# RN8XXX_V2 register map
File version: 1.0
Registers are 32-bit, read-write, reset 0x0 unless marked. A register's access mark holds for its fields unless they carry their own. Offsets are from the block's base; [hi:lo] are bit positions; {n}, {i} and the like mark numbered series.

## INTC — interrupt controller for off-chip interrupt requests
Base 0x40044000
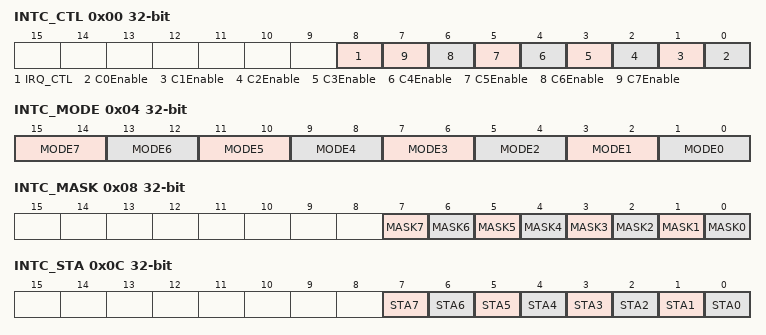
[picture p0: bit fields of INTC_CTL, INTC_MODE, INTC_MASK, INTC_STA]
0x00 INTC_CTL — INTC control register
  [8] IRQ_CTL — external interrupt mode selection
    0=disabled (INT0~INT7 not use IRQ_CTL to indicate interrupt, refer to STA.EXIT[7:0]); 1=enabled (INT0~INT7 share EXIT0 IRQ vector, check STA for which interrupt accour)
  [n] C{n}Enable (n=0..7) — external interrupt request channel {n} enable
    0=disabled (interrupt request disabled); 1=enabled (interrupt request enabled)
0x04 INTC_MODE
  [all] fields
    0=rising_edge (every rising edge found on input recognized as a valid interrupt request); 1=falling_edge (every falling edge found on input recognized as a valid interrupt request); 2=both_edge (both rising and falling edge found on input recognized as a valid interrupt request)
  [15:14] MODE7 — external interrupt request channel No.7 mode selection
  [13:12] MODE6 — external interrupt request channel No.6 mode selection
  [11:10] MODE5 — external interrupt request channel No.5 mode selection
  [9:8] MODE4 — external interrupt request channel No.4 mode selection
  [7:6] MODE3 — external interrupt request channel No.3 mode selection
  [5:4] MODE2 — external interrupt request channel No.2 mode selection
  [3:2] MODE1 — external interrupt request channel No.1 mode selection
  [1:0] MODE0 — external interrupt request channel No.0 mode selection
0x08 INTC_MASK
  [all] fields
    0=disabled; 1=enabled
  [7] MASK7 — external interrupt request channel No.7 mask selection
  [6] MASK6 — external interrupt request channel No.6 mask selection
  [5] MASK5 — external interrupt request channel No.5 mask selection
  [4] MASK4 — external interrupt request channel No.4 mask selection
  [3] MASK3 — external interrupt request channel No.3 mask selection
  [2] MASK2 — external interrupt request channel No.2 mask selection
  [1] MASK1 — external interrupt request channel No.1 mask selection
  [0] MASK0 — external interrupt request channel No.0 mask selection
0x0C INTC_STA — Extern interrupt status register
  [all] fields
    0=not_pending (no interrupt request event found); 1=pending ((one or more)interrupt request event found)
  [7] STA7 write-1-clears — external interrupt request channel No.7 raw status
  [6] STA6 write-1-clears — external interrupt request channel No.6 raw status
  [5] STA5 write-1-clears — external interrupt request channel No.5 raw status
  [4] STA4 write-1-clears — external interrupt request channel No.4 raw status
  [3] STA3 write-1-clears — external interrupt request channel No.3 raw status
  [2] STA2 write-1-clears — external interrupt request channel No.2 raw status
  [1] STA1 write-1-clears — external interrupt request channel No.1 raw status
  [0] STA0 write-1-clears — external interrupt request channel No.0 raw status

## I2C — I2C controller
Base 0x40024000
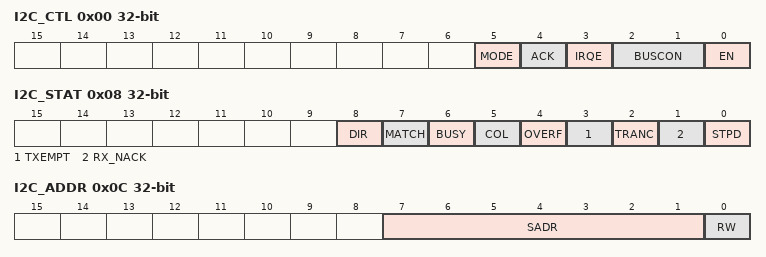
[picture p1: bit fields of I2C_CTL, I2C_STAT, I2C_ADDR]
0x00 I2C_CTL — control
  [5] MODE — mode selection
    0=slave (I2C slave mode); 1=master (I2C master mode)
  [4] ACK — ACK generation enable
    0=disable (do not generate ACK signal when ninth SCL (clock) received); 1=enable (generate ACK signal when ninth SCL (clock) received)
  [3] IRQE — interrupt enable
    0=disable (do not generate interrupt request); 1=enable (generate interrupt request when needed)
  [2:1] BUSCON — bus control signal generation
    0=no_action (do not generate any bus control signal); 1=start (generate I2C start signal); 2=stop (generate I2C stop signal); 3=reserved (do not use)
  [0] EN — module enable
    0=disable (transmit and receive engine disabled); 1=enable (transmit and receive engine enabled)
0x04 I2C_CLK reset 0x1 — clock config
  [2:0] CLKDIV — bus clock divisor
    0=hs0_d6 (high speed mode0 (divisor is 6).applicable when frequency of system clock is 1.8432MHz); 1=hs0_d10 (high speed mode1 (divisor is 10).applicable when frequency of system clock is 3.6864MHz); 2=hs0_d20/ls0_d20 (high speed mode2 (divisor is 20).applicable when frequency of system clock is 7.3728MHz. Or low speed mode0 (divisor is 20).applicable when frequency of system clock is 1.8432MHz.); 3=hs0_d38/ls0_d38 (high speed mode3 (divisor is 38).applicable when frequency of system clock is 14.7456MHz. Or low speed mode1 (divisor is 38).applicable when frequency of system clock is 3.6864MHz); 4=hs0_d76/ls0_d76 (high speed mode4 (divisor is 76).applicable when frequency of system clock is 29.4912MHz. Or low speed mode2 (divisor is 76).applicable when frequency of system clock is 7.3728MHz); 5=ls0_d152 (low speed mode3 (divisor is 152).applicable when frequency of system clock is 14.7456MHz); 6=ls0_d76 (low speed mode4 (divisor is 304).applicable when frequency of system clock is 29.4912MHz); 7=reserved2 (do not use)
0x08 I2C_STAT — status
  [8] DIR ro — bus transfer direction
    0=transmiting; 1=receive (receiving)
  [7] MATCH ro — address match
    0=no_match (no outstanding I2C slave address match event); 1=match (I2C slave address match event pending)
  [6] BUSY ro
    0=idle (no outstanding I2C transfer); 1=busy (I2C transfer in operation)
  [5] COL write-1-clears — bus collision
    0=no_collision (no outstanding collision event); 1=collision event pending
  [4] OVERF write-1-clears — recieve overflow
    0=no_receive_overflow (no outstanding receive overflow event); 1=receive overflow event pending
  [3] TXEMPT write-1-clears — transmit downflow error
    0=no_transmit_downflow (no outstanding trasmit downflow event); 1=transmit downflow event pending
  [2] TRANC write-1-clears — transmit over
    0=no_transmit_over (no outstanding trasmit over event); 1=transmit over event pending
  [1] RX_NACK write-1-clears — NACK
    0=no NACK found; 1=NACK found
  [0] STPD write-1-clears — stop detection
    0=no stop found; 1=stop found
0x0C I2C_ADDR — I2C slave device address register.
  [7:1] SADR — slave address(to match or to locate).writable only when no I2C transfere in operation
  [0] RW — bus direction
    0=transmit (to transmit); 1=receive (to receive)
0x10 I2C_DATA — transfer data
  [7:0] TRDAT
